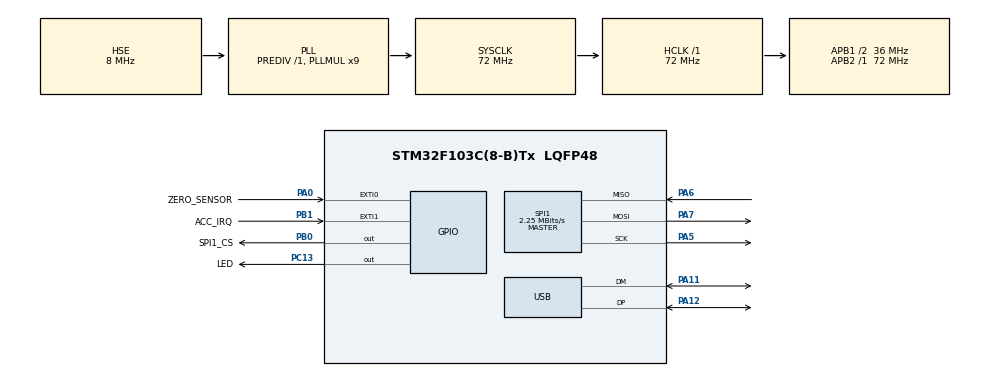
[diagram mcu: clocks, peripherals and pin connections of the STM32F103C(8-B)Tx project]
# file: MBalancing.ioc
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Mcu.Family=STM32F1
Mcu.Name=STM32F103C(8-B)Tx
Mcu.Package=LQFP48
NVIC.EXTI0_IRQn=true\:4\:0\:true\:false\:true\:true\:true
NVIC.EXTI1_IRQn=true\:3\:0\:true\:false\:true\:true\:true
NVIC.PriorityGroup=NVIC_PRIORITYGROUP_4
NVIC.USB_LP_CAN1_RX0_IRQn=true\:1\:0\:true\:false\:true\:false\:true
PA0-WKUP.GPIO_Label=ZERO_SENSOR
PA0-WKUP.GPIO_PuPd=GPIO_PULLUP
PA0-WKUP.Signal=GPXTI0
PA11.Mode=Device
PA11.Signal=USB_DM
PA12.Mode=Device
PA12.Signal=USB_DP
PA13.Mode=Serial_Wire
PA13.Signal=SYS_JTMS-SWDIO
PA14.Mode=Serial_Wire
PA14.Signal=SYS_JTCK-SWCLK
PA5.Mode=Full_Duplex_Master
PA5.Signal=SPI1_SCK
PA6.Mode=Full_Duplex_Master
PA6.Signal=SPI1_MISO
PA7.Mode=Full_Duplex_Master
PA7.Signal=SPI1_MOSI
PB0.GPIO_Label=SPI1_CS
PB0.Signal=GPIO_Output
PB1.GPIO_Label=ACC_IRQ
PB1.GPIO_PuPd=GPIO_PULLDOWN
PB1.Signal=GPXTI1
PC13-TAMPER-RTC.GPIO_Label=LED
PC13-TAMPER-RTC.Signal=GPIO_Output
PD0-OSC_IN.Mode=HSE-External-Oscillator
PD0-OSC_IN.Signal=RCC_OSC_IN
PD1-OSC_OUT.Mode=HSE-External-Oscillator
PD1-OSC_OUT.Signal=RCC_OSC_OUT
ProjectManager.HeapSize=0x200
ProjectManager.StackSize=0x400
ProjectManager.TargetToolchain=MDK-ARM V5
RCC.ADCPresc=RCC_ADCPCLK2_DIV6
RCC.AHBFreq_Value=72000000
RCC.APB1CLKDivider=RCC_HCLK_DIV2
RCC.APB1Freq_Value=36000000
RCC.APB1TimFreq_Value=72000000
RCC.APB2Freq_Value=72000000
RCC.APB2TimFreq_Value=72000000
RCC.HCLKFreq_Value=72000000
RCC.PLLMUL=RCC_PLL_MUL9
RCC.SYSCLKFreq_VALUE=72000000
RCC.SYSCLKSource=RCC_SYSCLKSOURCE_PLLCLK
RCC.USBFreq_Value=48000000
RCC.USBPrescaler=RCC_USBCLKSOURCE_PLL_DIV1_5
SPI1.BaudRatePrescaler=SPI_BAUDRATEPRESCALER_32
SPI1.CLKPhase=SPI_PHASE_2EDGE
SPI1.CLKPolarity=SPI_POLARITY_HIGH
SPI1.CalculateBaudRate=2.25 MBits/s
SPI1.Direction=SPI_DIRECTION_2LINES
SPI1.Mode=SPI_MODE_MASTER
SPI1.VirtualType=VM_MASTER
USB_DEVICE.CLASS_NAME_FS=CDC
USB_DEVICE.VirtualMode=Cdc
USB_DEVICE.VirtualModeFS=Cdc_FS
VP_TIM2_VS_ClockSourceINT.Mode=Internal
VP_USB_DEVICE_VS_USB_DEVICE_CDC_FS.Mode=CDC_FS
board=custom

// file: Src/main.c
/* USER CODE BEGIN Header */
/**
  ******************************************************************************
  * @file           : main.c
  * @brief          : Main program body
  ******************************************************************************
  * @attention
  *
  * <h2><center>&copy; Copyright (c) 2023 STMicroelectronics.
  * All rights reserved.</center></h2>
  *
  * This software component is licensed by ST under Ultimate Liberty license
  * SLA0044, the "License"; You may not use this file except in compliance with
  * the License. You may obtain a copy of the License at:
  *                             www.st.com/SLA0044
  *
  ******************************************************************************
  */
/* USER CODE END Header */
#include "main.h"
#include "usb_device.h"

/* USER CODE BEGIN Includes */
#include "usbd_cdc_if.h"
#include "acquisition.h"
/* USER CODE END Includes */

SPI_HandleTypeDef hspi1;

TIM_HandleTypeDef htim2;

/* USER CODE BEGIN PV */
/* Private variables ---------------------------------------------------------*/

/* USER CODE END PV */

void SystemClock_Config(void);
static void MX_GPIO_Init(void);
static void MX_SPI1_Init(void);
static void MX_TIM2_Init(void);
/* USER CODE BEGIN PFP */
/* Private function prototypes -----------------------------------------------*/

/* USER CODE END PFP */

int main(void)
{

  /* MCU Configuration--------------------------------------------------------*/

  /* Reset of all peripherals, Initializes the Flash interface and the Systick. */
  HAL_Init();

  /* Configure the system clock */
  SystemClock_Config();

  /* USER CODE BEGIN SysInit */
  cdc_usb_reset();
  /* USER CODE END SysInit */

  /* Initialize all configured peripherals */
  MX_GPIO_Init();
  MX_USB_DEVICE_Init();
  MX_SPI1_Init();
  MX_TIM2_Init();
  /* USER CODE BEGIN 2 */
  acquisition_init();
  /* USER CODE END 2 */

  /* Infinite loop */
  while (1)
  {

    /* USER CODE BEGIN 3 */
    acquisition_periodic_handler();
  }
  /* USER CODE END 3 */
}

void SystemClock_Config(void)
{
  RCC_OscInitTypeDef RCC_OscInitStruct = {0};
  RCC_ClkInitTypeDef RCC_ClkInitStruct = {0};
  RCC_PeriphCLKInitTypeDef PeriphClkInit = {0};

  /** Initializes the RCC Oscillators according to the specified parameters
  * in the RCC_OscInitTypeDef structure.
  */
  RCC_OscInitStruct.OscillatorType = RCC_OSCILLATORTYPE_HSE;
  RCC_OscInitStruct.HSEState = RCC_HSE_ON;
  RCC_OscInitStruct.HSEPredivValue = RCC_HSE_PREDIV_DIV1;
  RCC_OscInitStruct.HSIState = RCC_HSI_ON;
  RCC_OscInitStruct.PLL.PLLState = RCC_PLL_ON;
  RCC_OscInitStruct.PLL.PLLSource = RCC_PLLSOURCE_HSE;
  RCC_OscInitStruct.PLL.PLLMUL = RCC_PLL_MUL9;
  if (HAL_RCC_OscConfig(&RCC_OscInitStruct) != HAL_OK)
  {
    Error_Handler();
  }
  /** Initializes the CPU, AHB and APB buses clocks
  */
  RCC_ClkInitStruct.ClockType = RCC_CLOCKTYPE_HCLK|RCC_CLOCKTYPE_SYSCLK
                              |RCC_CLOCKTYPE_PCLK1|RCC_CLOCKTYPE_PCLK2;
  RCC_ClkInitStruct.SYSCLKSource = RCC_SYSCLKSOURCE_PLLCLK;
  RCC_ClkInitStruct.AHBCLKDivider = RCC_SYSCLK_DIV1;
  RCC_ClkInitStruct.APB1CLKDivider = RCC_HCLK_DIV2;
  RCC_ClkInitStruct.APB2CLKDivider = RCC_HCLK_DIV1;

  if (HAL_RCC_ClockConfig(&RCC_ClkInitStruct, FLASH_LATENCY_2) != HAL_OK)
  {
    Error_Handler();
  }
  PeriphClkInit.PeriphClockSelection = RCC_PERIPHCLK_USB;
  PeriphClkInit.UsbClockSelection = RCC_USBCLKSOURCE_PLL_DIV1_5;
  if (HAL_RCCEx_PeriphCLKConfig(&PeriphClkInit) != HAL_OK)
  {
    Error_Handler();
  }
}

static void MX_SPI1_Init(void)
{

  /* SPI1 parameter configuration*/
  hspi1.Instance = SPI1;
  hspi1.Init.Mode = SPI_MODE_MASTER;
  hspi1.Init.Direction = SPI_DIRECTION_2LINES;
  hspi1.Init.DataSize = SPI_DATASIZE_8BIT;
  hspi1.Init.CLKPolarity = SPI_POLARITY_HIGH;
  hspi1.Init.CLKPhase = SPI_PHASE_2EDGE;
  hspi1.Init.NSS = SPI_NSS_SOFT;
  hspi1.Init.BaudRatePrescaler = SPI_BAUDRATEPRESCALER_32;
  hspi1.Init.FirstBit = SPI_FIRSTBIT_MSB;
  hspi1.Init.TIMode = SPI_TIMODE_DISABLE;
  hspi1.Init.CRCCalculation = SPI_CRCCALCULATION_DISABLE;
  hspi1.Init.CRCPolynomial = 10;
  if (HAL_SPI_Init(&hspi1) != HAL_OK)
  {
    Error_Handler();
  }

}

static void MX_TIM2_Init(void)
{

  TIM_ClockConfigTypeDef sClockSourceConfig = {0};
  TIM_MasterConfigTypeDef sMasterConfig = {0};

  htim2.Instance = TIM2;
  htim2.Init.Prescaler = 0;
  htim2.Init.CounterMode = TIM_COUNTERMODE_UP;
  htim2.Init.Period = 65535;
  htim2.Init.ClockDivision = TIM_CLOCKDIVISION_DIV1;
  htim2.Init.AutoReloadPreload = TIM_AUTORELOAD_PRELOAD_DISABLE;
  if (HAL_TIM_Base_Init(&htim2) != HAL_OK)
  {
    Error_Handler();
  }
  sClockSourceConfig.ClockSource = TIM_CLOCKSOURCE_INTERNAL;
  if (HAL_TIM_ConfigClockSource(&htim2, &sClockSourceConfig) != HAL_OK)
  {
    Error_Handler();
  }
  sMasterConfig.MasterOutputTrigger = TIM_TRGO_RESET;
  sMasterConfig.MasterSlaveMode = TIM_MASTERSLAVEMODE_DISABLE;
  if (HAL_TIMEx_MasterConfigSynchronization(&htim2, &sMasterConfig) != HAL_OK)
  {
    Error_Handler();
  }

}

static void MX_GPIO_Init(void)
{
  GPIO_InitTypeDef GPIO_InitStruct = {0};

  /* GPIO Ports Clock Enable */
  __HAL_RCC_GPIOC_CLK_ENABLE();
  __HAL_RCC_GPIOD_CLK_ENABLE();
  __HAL_RCC_GPIOA_CLK_ENABLE();
  __HAL_RCC_GPIOB_CLK_ENABLE();

  /*Configure GPIO pin Output Level */
  HAL_GPIO_WritePin(LED_GPIO_Port, LED_Pin, GPIO_PIN_RESET);

  /*Configure GPIO pin Output Level */
  HAL_GPIO_WritePin(SPI1_CS_GPIO_Port, SPI1_CS_Pin, GPIO_PIN_RESET);

  /*Configure GPIO pin : LED_Pin */
  GPIO_InitStruct.Pin = LED_Pin;
  GPIO_InitStruct.Mode = GPIO_MODE_OUTPUT_PP;
  GPIO_InitStruct.Pull = GPIO_NOPULL;
  GPIO_InitStruct.Speed = GPIO_SPEED_FREQ_LOW;
  HAL_GPIO_Init(LED_GPIO_Port, &GPIO_InitStruct);

  /*Configure GPIO pin : ZERO_SENSOR_Pin */
  GPIO_InitStruct.Pin = ZERO_SENSOR_Pin;
  GPIO_InitStruct.Mode = GPIO_MODE_IT_RISING;
  GPIO_InitStruct.Pull = GPIO_PULLUP;
  HAL_GPIO_Init(ZERO_SENSOR_GPIO_Port, &GPIO_InitStruct);

  /*Configure GPIO pin : SPI1_CS_Pin */
  GPIO_InitStruct.Pin = SPI1_CS_Pin;
  GPIO_InitStruct.Mode = GPIO_MODE_OUTPUT_PP;
  GPIO_InitStruct.Pull = GPIO_NOPULL;
  GPIO_InitStruct.Speed = GPIO_SPEED_FREQ_LOW;
  HAL_GPIO_Init(SPI1_CS_GPIO_Port, &GPIO_InitStruct);

  /*Configure GPIO pin : ACC_IRQ_Pin */
  GPIO_InitStruct.Pin = ACC_IRQ_Pin;
  GPIO_InitStruct.Mode = GPIO_MODE_IT_RISING;
  GPIO_InitStruct.Pull = GPIO_PULLDOWN;
  HAL_GPIO_Init(ACC_IRQ_GPIO_Port, &GPIO_InitStruct);

  /* EXTI interrupt init*/
  HAL_NVIC_SetPriority(EXTI0_IRQn, 4, 0);
  HAL_NVIC_EnableIRQ(EXTI0_IRQn);

  HAL_NVIC_SetPriority(EXTI1_IRQn, 3, 0);
  HAL_NVIC_EnableIRQ(EXTI1_IRQn);

}

void Error_Handler(void)
{
  while(1)
  {
  }
}

/************************ (C) COPYRIGHT STMicroelectronics *****END OF FILE****/
